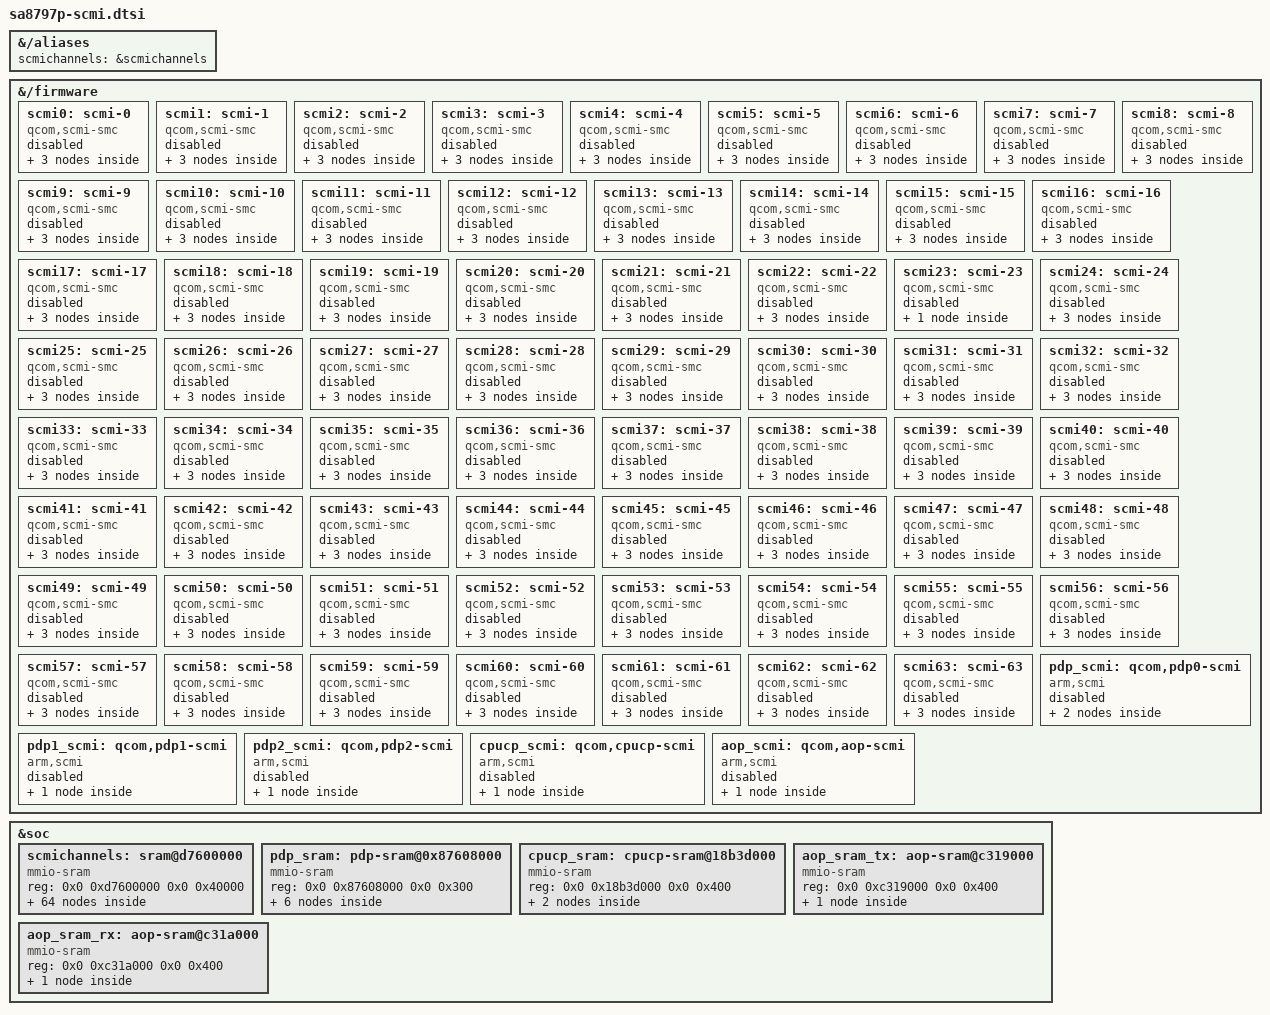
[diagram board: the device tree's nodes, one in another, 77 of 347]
/*
 * Copyright (c) Qualcomm Technologies, Inc. and/or its subsidiaries.
 * SPDX-License-Identifier: BSD-3-Clause
 */

#include <dt-bindings/interrupt-controller/arm-gic.h>
#include "oot-dt-bindings/qcom-ipcc-sa8797p.h"

&{/aliases} {
	scmichannels = &scmichannels;
};

&{/firmware} {
	scmi0: scmi-0 {
		compatible = "qcom,scmi-smc";
		arm,smc-id = <0xc6008012>;
		shmem = <&shmem0>;

		interrupts = <GIC_SPI 963 IRQ_TYPE_EDGE_RISING>;
		interrupt-names = "a2p";

		#address-cells = <1>;
		#size-cells = <0>;

		status = "disabled";

		scmi0_pd: protocol@11 {
			reg = <0x11>;
			#power-domain-cells = <1>;
		};

		scmi0_dvfs: protocol@13 {
			reg = <0x13>;
			#power-domain-cells = <1>;
		};

		scmi0_rst: protocol@16 {
			reg = <0x16>;
			#reset-cells = <1>;
		};
	};

	scmi1: scmi-1 {
		compatible = "qcom,scmi-smc";
		arm,smc-id = <0xc6008012>;
		shmem = <&shmem1>;

		interrupts = <GIC_SPI 964 IRQ_TYPE_EDGE_RISING>;
		interrupt-names = "a2p";

		#address-cells = <1>;
		#size-cells = <0>;

		status = "disabled";

		scmi1_pd: protocol@11 {
			reg = <0x11>;
			#power-domain-cells = <1>;
		};

		scmi1_dvfs: protocol@13 {
			reg = <0x13>;
			#power-domain-cells = <1>;
		};

		scmi1_rst: protocol@16 {
			reg = <0x16>;
			#reset-cells = <1>;
		};
	};

	scmi2: scmi-2 {
		compatible = "qcom,scmi-smc";
		arm,smc-id = <0xc6008012>;
		shmem = <&shmem2>;

		interrupts = <GIC_SPI 965 IRQ_TYPE_EDGE_RISING>;
		interrupt-names = "a2p";

		#address-cells = <1>;
		#size-cells = <0>;

		status = "disabled";

		scmi2_pd: protocol@11 {
			reg = <0x11>;
			#power-domain-cells = <1>;
		};

		scmi2_dvfs: protocol@13 {
			reg = <0x13>;
			#power-domain-cells = <1>;
		};

		scmi2_rst: protocol@16 {
			reg = <0x16>;
			#reset-cells = <1>;
		};
	};

	scmi3: scmi-3 {
		compatible = "qcom,scmi-smc";
		arm,smc-id = <0xc6008012>;
		shmem = <&shmem3>;

		interrupts = <GIC_SPI 966 IRQ_TYPE_EDGE_RISING>;
		interrupt-names = "a2p";

		#address-cells = <1>;
		#size-cells = <0>;

		status = "disabled";

		scmi3_pd: protocol@11 {
			reg = <0x11>;
			#power-domain-cells = <1>;
		};

		scmi3_dvfs: protocol@13 {
			reg = <0x13>;
			#power-domain-cells = <1>;
		};

		scmi3_rst: protocol@16 {
			reg = <0x16>;
			#reset-cells = <1>;
		};
	};

	scmi4: scmi-4 {
		compatible = "qcom,scmi-smc";
		arm,smc-id = <0xc6008012>;
		shmem = <&shmem4>;

		interrupts = <GIC_SPI 967 IRQ_TYPE_EDGE_RISING>;
		interrupt-names = "a2p";

		#address-cells = <1>;
		#size-cells = <0>;

		status = "disabled";

		scmi4_pd: protocol@11 {
			reg = <0x11>;
			#power-domain-cells = <1>;
		};

		scmi4_dvfs: protocol@13 {
			reg = <0x13>;
			#power-domain-cells = <1>;
		};

		scmi4_rst: protocol@16 {
			reg = <0x16>;
			#reset-cells = <1>;
		};
	};

	scmi5: scmi-5 {
		compatible = "qcom,scmi-smc";
		arm,smc-id = <0xc6008012>;
		shmem = <&shmem5>;

		interrupts = <GIC_SPI 968 IRQ_TYPE_EDGE_RISING>;
		interrupt-names = "a2p";

		#address-cells = <1>;
		#size-cells = <0>;

		status = "disabled";

		scmi5_pd: protocol@11 {
			reg = <0x11>;
			#power-domain-cells = <1>;
		};

		scmi5_dvfs: protocol@13 {
			reg = <0x13>;
			#power-domain-cells = <1>;
		};

		scmi5_rst: protocol@16 {
			reg = <0x16>;
			#reset-cells = <1>;
		};
	};

	scmi6: scmi-6 {
		compatible = "qcom,scmi-smc";
		arm,smc-id = <0xc6008012>;
		shmem = <&shmem6>;

		interrupts = <GIC_SPI 969 IRQ_TYPE_EDGE_RISING>;
		interrupt-names = "a2p";

		#address-cells = <1>;
		#size-cells = <0>;

		status = "disabled";

		scmi6_pd: protocol@11 {
			reg = <0x11>;
			#power-domain-cells = <1>;
		};

		scmi6_dvfs: protocol@13 {
			reg = <0x13>;
			#power-domain-cells = <1>;
		};

		scmi6_rst: protocol@16 {
			reg = <0x16>;
			#reset-cells = <1>;
		};
	};

	scmi7: scmi-7 {
		compatible = "qcom,scmi-smc";
		arm,smc-id = <0xc6008012>;
		shmem = <&shmem7>;

		interrupts = <GIC_SPI 970 IRQ_TYPE_EDGE_RISING>;
		interrupt-names = "a2p";

		#address-cells = <1>;
		#size-cells = <0>;

		status = "disabled";

		scmi7_pd: protocol@11 {
			reg = <0x11>;
			#power-domain-cells = <1>;
		};

		scmi7_dvfs: protocol@13 {
			reg = <0x13>;
			#power-domain-cells = <1>;
		};

		scmi7_rst: protocol@16 {
			reg = <0x16>;
			#reset-cells = <1>;
		};
	};

	scmi8: scmi-8 {
		compatible = "qcom,scmi-smc";
		arm,smc-id = <0xc6008012>;
		shmem = <&shmem8>;

		interrupts = <GIC_SPI 971 IRQ_TYPE_EDGE_RISING>;
		interrupt-names = "a2p";

		#address-cells = <1>;
		#size-cells = <0>;

		status = "disabled";

		scmi8_pd: protocol@11 {
			reg = <0x11>;
			#power-domain-cells = <1>;
		};

		scmi8_dvfs: protocol@13 {
			reg = <0x13>;
			#power-domain-cells = <1>;
		};

		scmi8_rst: protocol@16 {
			reg = <0x16>;
			#reset-cells = <1>;
		};
	};

	scmi9: scmi-9 {
		compatible = "qcom,scmi-smc";
		arm,smc-id = <0xc6008012>;
		shmem = <&shmem9>;

		interrupts = <GIC_SPI 972 IRQ_TYPE_EDGE_RISING>;
		interrupt-names = "a2p";

		#address-cells = <1>;
		#size-cells = <0>;

		status = "disabled";

		scmi9_pd: protocol@11 {
			reg = <0x11>;
			#power-domain-cells = <1>;
		};

		scmi9_dvfs: protocol@13 {
			reg = <0x13>;
			#power-domain-cells = <1>;
		};

		scmi9_rst: protocol@16 {
			reg = <0x16>;
			#reset-cells = <1>;
		};
	};

	scmi10: scmi-10 {
		compatible = "qcom,scmi-smc";
		arm,smc-id = <0xc6008012>;
		shmem = <&shmem10>;

		interrupts = <GIC_SPI 973 IRQ_TYPE_EDGE_RISING>;
		interrupt-names = "a2p";

		#address-cells = <1>;
		#size-cells = <0>;

		status = "disabled";

		scmi10_pd: protocol@11 {
			reg = <0x11>;
			#power-domain-cells = <1>;
		};

		scmi10_dvfs: protocol@13 {
			reg = <0x13>;
			#power-domain-cells = <1>;
		};

		scmi10_rst: protocol@16 {
			reg = <0x16>;
			#reset-cells = <1>;
		};
	};

	scmi11: scmi-11 {
		compatible = "qcom,scmi-smc";
		arm,smc-id = <0xc6008012>;
		shmem = <&shmem11>;

		interrupts = <GIC_SPI 974 IRQ_TYPE_EDGE_RISING>;
		interrupt-names = "a2p";

		#address-cells = <1>;
		#size-cells = <0>;

		status = "disabled";

		scmi11_pd: protocol@11 {
			reg = <0x11>;
			#power-domain-cells = <1>;
		};

		scmi11_dvfs: protocol@13 {
			reg = <0x13>;
			#power-domain-cells = <1>;
		};

		scmi11_rst: protocol@16 {
			reg = <0x16>;
			#reset-cells = <1>;
		};
	};

	scmi12: scmi-12 {
		compatible = "qcom,scmi-smc";
		arm,smc-id = <0xc6008012>;
		shmem = <&shmem12>;

		interrupts = <GIC_SPI 975 IRQ_TYPE_EDGE_RISING>;
		interrupt-names = "a2p";

		#address-cells = <1>;
		#size-cells = <0>;

		status = "disabled";

		scmi12_pd: protocol@11 {
			reg = <0x11>;
			#power-domain-cells = <1>;
		};

		scmi12_dvfs: protocol@13 {
			reg = <0x13>;
			#power-domain-cells = <1>;
		};

		scmi12_rst: protocol@16 {
			reg = <0x16>;
			#reset-cells = <1>;
		};
	};

	scmi13: scmi-13 {
		compatible = "qcom,scmi-smc";
		arm,smc-id = <0xc6008012>;
		shmem = <&shmem13>;

		interrupts = <GIC_SPI 976 IRQ_TYPE_EDGE_RISING>;
		interrupt-names = "a2p";

		#address-cells = <1>;
		#size-cells = <0>;

		status = "disabled";

		scmi13_pd: protocol@11 {
			reg = <0x11>;
			#power-domain-cells = <1>;
		};

		scmi13_dvfs: protocol@13 {
			reg = <0x13>;
			#power-domain-cells = <1>;
		};

		scmi13_rst: protocol@16 {
			reg = <0x16>;
			#reset-cells = <1>;
		};
	};

	scmi14: scmi-14 {
		compatible = "qcom,scmi-smc";
		arm,smc-id = <0xc6008012>;
		shmem = <&shmem14>;

		interrupts = <GIC_SPI 977 IRQ_TYPE_EDGE_RISING>;
		interrupt-names = "a2p";

		#address-cells = <1>;
		#size-cells = <0>;

		status = "disabled";

		scmi14_pd: protocol@11 {
			reg = <0x11>;
			#power-domain-cells = <1>;
		};

		scmi14_dvfs: protocol@13 {
			reg = <0x13>;
			#power-domain-cells = <1>;
		};

		scmi14_rst: protocol@16 {
			reg = <0x16>;
			#reset-cells = <1>;
		};
	};

	scmi15: scmi-15 {
		compatible = "qcom,scmi-smc";
		arm,smc-id = <0xc6008012>;
		shmem = <&shmem15>;

		interrupts = <GIC_SPI 978 IRQ_TYPE_EDGE_RISING>;
		interrupt-names = "a2p";

		#address-cells = <1>;
		#size-cells = <0>;

		status = "disabled";

		scmi15_pd: protocol@11 {
			reg = <0x11>;
			#power-domain-cells = <1>;
		};

		scmi15_dvfs: protocol@13 {
			reg = <0x13>;
			#power-domain-cells = <1>;
		};

		scmi15_rst: protocol@16 {
			reg = <0x16>;
			#reset-cells = <1>;
		};
	};

	scmi16: scmi-16 {
		compatible = "qcom,scmi-smc";
		arm,smc-id = <0xc6008012>;
		shmem = <&shmem16>;

		interrupts = <GIC_SPI 979 IRQ_TYPE_EDGE_RISING>;
		interrupt-names = "a2p";

		#address-cells = <1>;
		#size-cells = <0>;

		status = "disabled";

		scmi16_pd: protocol@11 {
			reg = <0x11>;
			#power-domain-cells = <1>;
		};

		scmi16_dvfs: protocol@13 {
			reg = <0x13>;
			#power-domain-cells = <1>;
		};

		scmi16_rst: protocol@16 {
			reg = <0x16>;
			#reset-cells = <1>;
		};
	};

	scmi17: scmi-17 {
		compatible = "qcom,scmi-smc";
		arm,smc-id = <0xc6008012>;
		shmem = <&shmem17>;

		interrupts = <GIC_SPI 980 IRQ_TYPE_EDGE_RISING>;
		interrupt-names = "a2p";

		#address-cells = <1>;
		#size-cells = <0>;

		status = "disabled";

		scmi17_pd: protocol@11 {
			reg = <0x11>;
			#power-domain-cells = <1>;
		};

		scmi17_dvfs: protocol@13 {
			reg = <0x13>;
			#power-domain-cells = <1>;
		};

		scmi17_rst: protocol@16 {
			reg = <0x16>;
			#reset-cells = <1>;
		};
	};

	scmi18: scmi-18 {
		compatible = "qcom,scmi-smc";
		arm,smc-id = <0xc6008012>;
		shmem = <&shmem18>;

		interrupts = <GIC_SPI 981 IRQ_TYPE_EDGE_RISING>;
		interrupt-names = "a2p";

		#address-cells = <1>;
		#size-cells = <0>;

		status = "disabled";

		scmi18_pd: protocol@11 {
			reg = <0x11>;
			#power-domain-cells = <1>;
		};

		scmi18_dvfs: protocol@13 {
			reg = <0x13>;
			#power-domain-cells = <1>;
		};

		scmi18_rst: protocol@16 {
			reg = <0x16>;
			#reset-cells = <1>;
		};
	};

	scmi19: scmi-19 {
		compatible = "qcom,scmi-smc";
		arm,smc-id = <0xc6008012>;
		shmem = <&shmem19>;

		interrupts = <GIC_SPI 982 IRQ_TYPE_EDGE_RISING>;
		interrupt-names = "a2p";

		#address-cells = <1>;
		#size-cells = <0>;

		status = "disabled";

		scmi19_pd: protocol@11 {
			reg = <0x11>;
			#power-domain-cells = <1>;
		};

		scmi19_dvfs: protocol@13 {
			reg = <0x13>;
			#power-domain-cells = <1>;
		};

		scmi19_rst: protocol@16 {
			reg = <0x16>;
			#reset-cells = <1>;
		};
	};

	scmi20: scmi-20 {
		compatible = "qcom,scmi-smc";
		arm,smc-id = <0xc6008012>;
		shmem = <&shmem20>;

		interrupts = <GIC_SPI 983 IRQ_TYPE_EDGE_RISING>;
		interrupt-names = "a2p";

		#address-cells = <1>;
		#size-cells = <0>;

		status = "disabled";

		scmi20_pd: protocol@11 {
			reg = <0x11>;
			#power-domain-cells = <1>;
		};

		scmi20_dvfs: protocol@13 {
			reg = <0x13>;
			#power-domain-cells = <1>;
		};

		scmi20_rst: protocol@16 {
			reg = <0x16>;
			#reset-cells = <1>;
		};
	};

	scmi21: scmi-21 {
		compatible = "qcom,scmi-smc";
		arm,smc-id = <0xc6008012>;
		shmem = <&shmem21>;

		interrupts = <GIC_SPI 984 IRQ_TYPE_EDGE_RISING>;
		interrupt-names = "a2p";

		#address-cells = <1>;
		#size-cells = <0>;

		status = "disabled";

		scmi21_pd: protocol@11 {
			reg = <0x11>;
			#power-domain-cells = <1>;
		};

		scmi21_dvfs: protocol@13 {
			reg = <0x13>;
			#power-domain-cells = <1>;
		};

		scmi21_rst: protocol@16 {
			reg = <0x16>;
			#reset-cells = <1>;
		};
	};

	scmi22: scmi-22 {
		compatible = "qcom,scmi-smc";
		arm,smc-id = <0xc6008012>;
		shmem = <&shmem22>;

		interrupts = <GIC_SPI 985 IRQ_TYPE_EDGE_RISING>;
		interrupt-names = "a2p";

		#address-cells = <1>;
		#size-cells = <0>;

		status = "disabled";

		scmi22_pd: protocol@11 {
			reg = <0x11>;
			#power-domain-cells = <1>;
		};

		scmi22_dvfs: protocol@13 {
			reg = <0x13>;
			#power-domain-cells = <1>;
		};

		scmi22_rst: protocol@16 {
			reg = <0x16>;
			#reset-cells = <1>;
		};
	};

	scmi23: scmi-23 {
		compatible = "qcom,scmi-smc";
		arm,smc-id = <0xc6008012>;
		shmem = <&shmem23>;

		interrupts = <GIC_SPI 986 IRQ_TYPE_EDGE_RISING>;
		interrupt-names = "a2p";

		#address-cells = <1>;
		#size-cells = <0>;

		status = "disabled";

		scmi23_sensor: protocol@15 {
			reg = <0x15>;
			#thermal-sensor-cells = <1>;
		};
	};

	scmi24: scmi-24 {
		compatible = "qcom,scmi-smc";
		arm,smc-id = <0xc6008012>;
		shmem = <&shmem24>;

		interrupts = <GIC_SPI 987 IRQ_TYPE_EDGE_RISING>;
		interrupt-names = "a2p";

		#address-cells = <1>;
		#size-cells = <0>;

		status = "disabled";

		scmi24_pd: protocol@11 {
			reg = <0x11>;
			#power-domain-cells = <1>;
		};

		scmi24_dvfs: protocol@13 {
			reg = <0x13>;
			#power-domain-cells = <1>;
		};

		scmi24_rst: protocol@16 {
			reg = <0x16>;
			#reset-cells = <1>;
		};
	};

	scmi25: scmi-25 {
		compatible = "qcom,scmi-smc";
		arm,smc-id = <0xc6008012>;
		shmem = <&shmem25>;

		interrupts = <GIC_ESPI 0 IRQ_TYPE_EDGE_RISING>;
		interrupt-names = "a2p";

		#address-cells = <1>;
		#size-cells = <0>;

		status = "disabled";

		scmi25_pd: protocol@11 {
			reg = <0x11>;
			#power-domain-cells = <1>;
		};

		scmi25_dvfs: protocol@13 {
			reg = <0x13>;
			#power-domain-cells = <1>;
		};

		scmi25_rst: protocol@16 {
			reg = <0x16>;
			#reset-cells = <1>;
		};
	};

	scmi26: scmi-26 {
		compatible = "qcom,scmi-smc";
		arm,smc-id = <0xc6008012>;
		shmem = <&shmem26>;

		interrupts = <GIC_ESPI 1 IRQ_TYPE_EDGE_RISING>;
		interrupt-names = "a2p";

		#address-cells = <1>;
		#size-cells = <0>;

		status = "disabled";

		scmi26_pd: protocol@11 {
			reg = <0x11>;
			#power-domain-cells = <1>;
		};

		scmi26_dvfs: protocol@13 {
			reg = <0x13>;
			#power-domain-cells = <1>;
		};

		scmi26_rst: protocol@16 {
			reg = <0x16>;
			#reset-cells = <1>;
		};
	};

	scmi27: scmi-27 {
		compatible = "qcom,scmi-smc";
		arm,smc-id = <0xc6008012>;
		shmem = <&shmem27>;

		interrupts = <GIC_ESPI 2 IRQ_TYPE_EDGE_RISING>;
		interrupt-names = "a2p";

		#address-cells = <1>;
		#size-cells = <0>;

		status = "disabled";

		scmi27_pd: protocol@11 {
			reg = <0x11>;
			#power-domain-cells = <1>;
		};

		scmi27_dvfs: protocol@13 {
			reg = <0x13>;
			#power-domain-cells = <1>;
		};

		scmi27_rst: protocol@16 {
			reg = <0x16>;
			#reset-cells = <1>;
		};
	};

	scmi28: scmi-28 {
		compatible = "qcom,scmi-smc";
		arm,smc-id = <0xc6008012>;
		shmem = <&shmem28>;

		interrupts = <GIC_ESPI 3 IRQ_TYPE_EDGE_RISING>;
		interrupt-names = "a2p";

		#address-cells = <1>;
		#size-cells = <0>;

		status = "disabled";

		scmi28_pd: protocol@11 {
			reg = <0x11>;
			#power-domain-cells = <1>;
		};

		scmi28_dvfs: protocol@13 {
			reg = <0x13>;
			#power-domain-cells = <1>;
		};

		scmi28_rst: protocol@16 {
			reg = <0x16>;
			#reset-cells = <1>;
		};
	};

	scmi29: scmi-29 {
		compatible = "qcom,scmi-smc";
		arm,smc-id = <0xc6008012>;
		shmem = <&shmem29>;

		interrupts = <GIC_ESPI 4 IRQ_TYPE_EDGE_RISING>;
		interrupt-names = "a2p";

		#address-cells = <1>;
		#size-cells = <0>;

		status = "disabled";

		scmi29_pd: protocol@11 {
			reg = <0x11>;
			#power-domain-cells = <1>;
		};

		scmi29_dvfs: protocol@13 {
			reg = <0x13>;
			#power-domain-cells = <1>;
		};

		scmi29_rst: protocol@16 {
			reg = <0x16>;
			#reset-cells = <1>;
		};
	};

	scmi30: scmi-30 {
		compatible = "qcom,scmi-smc";
		arm,smc-id = <0xc6008012>;
		shmem = <&shmem30>;

		interrupts = <GIC_ESPI 5 IRQ_TYPE_EDGE_RISING>;
		interrupt-names = "a2p";

		#address-cells = <1>;
		#size-cells = <0>;

		status = "disabled";

		scmi30_pd: protocol@11 {
			reg = <0x11>;
			#power-domain-cells = <1>;
		};

		scmi30_dvfs: protocol@13 {
			reg = <0x13>;
			#power-domain-cells = <1>;
		};

		scmi30_rst: protocol@16 {
			reg = <0x16>;
			#reset-cells = <1>;
		};
	};

	scmi31: scmi-31 {
		compatible = "qcom,scmi-smc";
		arm,smc-id = <0xc6008012>;
		shmem = <&shmem31>;

		interrupts = <GIC_ESPI 6 IRQ_TYPE_EDGE_RISING>;
		interrupt-names = "a2p";

		#address-cells = <1>;
		#size-cells = <0>;

		status = "disabled";

		scmi31_pd: protocol@11 {
			reg = <0x11>;
			#power-domain-cells = <1>;
		};

		scmi31_dvfs: protocol@13 {
			reg = <0x13>;
			#power-domain-cells = <1>;
		};

		scmi31_rst: protocol@16 {
			reg = <0x16>;
			#reset-cells = <1>;
		};
	};

	scmi32: scmi-32 {
		compatible = "qcom,scmi-smc";
		arm,smc-id = <0xc6008012>;
		shmem = <&shmem32>;

		interrupts = <GIC_ESPI 7 IRQ_TYPE_EDGE_RISING>;
		interrupt-names = "a2p";

		#address-cells = <1>;
		#size-cells = <0>;

		status = "disabled";

		scmi32_pd: protocol@11 {
			reg = <0x11>;
			#power-domain-cells = <1>;
		};

		scmi32_dvfs: protocol@13 {
			reg = <0x13>;
			#power-domain-cells = <1>;
		};

		scmi32_rst: protocol@16 {
			reg = <0x16>;
			#reset-cells = <1>;
		};
	};

	scmi33: scmi-33 {
		compatible = "qcom,scmi-smc";
		arm,smc-id = <0xc6008012>;
		shmem = <&shmem33>;

		interrupts = <GIC_ESPI 8 IRQ_TYPE_EDGE_RISING>;
		interrupt-names = "a2p";

		#address-cells = <1>;
		#size-cells = <0>;

		status = "disabled";

		scmi33_pd: protocol@11 {
			reg = <0x11>;
			#power-domain-cells = <1>;
		};

		scmi33_dvfs: protocol@13 {
			reg = <0x13>;
			#power-domain-cells = <1>;
		};

		scmi33_rst: protocol@16 {
			reg = <0x16>;
			#reset-cells = <1>;
		};
	};

	scmi34: scmi-34 {
		compatible = "qcom,scmi-smc";
		arm,smc-id = <0xc6008012>;
		shmem = <&shmem34>;

		interrupts = <GIC_ESPI 9 IRQ_TYPE_EDGE_RISING>;
		interrupt-names = "a2p";

		#address-cells = <1>;
		#size-cells = <0>;

		status = "disabled";

		scmi34_pd: protocol@11 {
			reg = <0x11>;
			#power-domain-cells = <1>;
		};

		scmi34_dvfs: protocol@13 {
			reg = <0x13>;
			#power-domain-cells = <1>;
		};

		scmi34_rst: protocol@16 {
			reg = <0x16>;
			#reset-cells = <1>;
		};
	};

	scmi35: scmi-35 {
		compatible = "qcom,scmi-smc";
		arm,smc-id = <0xc6008012>;
		shmem = <&shmem35>;

		interrupts = <GIC_ESPI 10 IRQ_TYPE_EDGE_RISING>;
		interrupt-names = "a2p";

		#address-cells = <1>;
		#size-cells = <0>;

		status = "disabled";

		scmi35_pd: protocol@11 {
			reg = <0x11>;
			#power-domain-cells = <1>;
		};

		scmi35_dvfs: protocol@13 {
			reg = <0x13>;
			#power-domain-cells = <1>;
		};

		scmi35_rst: protocol@16 {
			reg = <0x16>;
			#reset-cells = <1>;
		};
	};

	scmi36: scmi-36 {
		compatible = "qcom,scmi-smc";
		arm,smc-id = <0xc6008012>;
		shmem = <&shmem36>;

		interrupts = <GIC_ESPI 11 IRQ_TYPE_EDGE_RISING>;
		interrupt-names = "a2p";

		#address-cells = <1>;
		#size-cells = <0>;

		status = "disabled";

		scmi36_pd: protocol@11 {
			reg = <0x11>;
			#power-domain-cells = <1>;
		};

		scmi36_dvfs: protocol@13 {
			reg = <0x13>;
			#power-domain-cells = <1>;
		};

		scmi36_rst: protocol@16 {
			reg = <0x16>;
			#reset-cells = <1>;
		};
	};

	scmi37: scmi-37 {
		compatible = "qcom,scmi-smc";
		arm,smc-id = <0xc6008012>;
		shmem = <&shmem37>;

		interrupts = <GIC_ESPI 12 IRQ_TYPE_EDGE_RISING>;
		interrupt-names = "a2p";

		#address-cells = <1>;
		#size-cells = <0>;

		status = "disabled";

		scmi37_pd: protocol@11 {
			reg = <0x11>;
			#power-domain-cells = <1>;
		};

		scmi37_dvfs: protocol@13 {
			reg = <0x13>;
			#power-domain-cells = <1>;
		};

		scmi37_rst: protocol@16 {
			reg = <0x16>;
			#reset-cells = <1>;
		};
	};

	scmi38: scmi-38 {
		compatible = "qcom,scmi-smc";
		arm,smc-id = <0xc6008012>;
		shmem = <&shmem38>;

		interrupts = <GIC_ESPI 13 IRQ_TYPE_EDGE_RISING>;
		interrupt-names = "a2p";

		#address-cells = <1>;
		#size-cells = <0>;

		status = "disabled";

		scmi38_pd: protocol@11 {
			reg = <0x11>;
			#power-domain-cells = <1>;
		};

		scmi38_dvfs: protocol@13 {
			reg = <0x13>;
			#power-domain-cells = <1>;
		};

		scmi38_rst: protocol@16 {
			reg = <0x16>;
			#reset-cells = <1>;
		};
	};

	scmi39: scmi-39 {
		compatible = "qcom,scmi-smc";
		arm,smc-id = <0xc6008012>;
		shmem = <&shmem39>;

		interrupts = <GIC_ESPI 14 IRQ_TYPE_EDGE_RISING>;
		interrupt-names = "a2p";

		#address-cells = <1>;
		#size-cells = <0>;

		status = "disabled";

		scmi39_pd: protocol@11 {
			reg = <0x11>;
			#power-domain-cells = <1>;
		};

		scmi39_dvfs: protocol@13 {
			reg = <0x13>;
			#power-domain-cells = <1>;
		};

		scmi39_rst: protocol@16 {
			reg = <0x16>;
			#reset-cells = <1>;
		};
	};

	scmi40: scmi-40 {
		compatible = "qcom,scmi-smc";
		arm,smc-id = <0xc6008012>;
		shmem = <&shmem40>;

		interrupts = <GIC_ESPI 15 IRQ_TYPE_EDGE_RISING>;
		interrupt-names = "a2p";

		#address-cells = <1>;
		#size-cells = <0>;

		status = "disabled";

		scmi40_pd: protocol@11 {
			reg = <0x11>;
			#power-domain-cells = <1>;
		};

		scmi40_dvfs: protocol@13 {
			reg = <0x13>;
			#power-domain-cells = <1>;
		};

		scmi40_rst: protocol@16 {
			reg = <0x16>;
			#reset-cells = <1>;
		};
	};

	scmi41: scmi-41 {
		compatible = "qcom,scmi-smc";
		arm,smc-id = <0xc6008012>;
		shmem = <&shmem41>;

		interrupts = <GIC_ESPI 16 IRQ_TYPE_EDGE_RISING>;
		interrupt-names = "a2p";

		#address-cells = <1>;
		#size-cells = <0>;

		status = "disabled";

		scmi41_pd: protocol@11 {
			reg = <0x11>;
			#power-domain-cells = <1>;
		};

		scmi41_dvfs: protocol@13 {
			reg = <0x13>;
			#power-domain-cells = <1>;
		};

		scmi41_rst: protocol@16 {
			reg = <0x16>;
			#reset-cells = <1>;
		};
	};

	scmi42: scmi-42 {
		compatible = "qcom,scmi-smc";
		arm,smc-id = <0xc6008012>;
		shmem = <&shmem42>;

		interrupts = <GIC_ESPI 17 IRQ_TYPE_EDGE_RISING>;
		interrupt-names = "a2p";

		#address-cells = <1>;
		#size-cells = <0>;

		status = "disabled";

		scmi42_pd: protocol@11 {
			reg = <0x11>;
			#power-domain-cells = <1>;
		};

		scmi42_dvfs: protocol@13 {
			reg = <0x13>;
			#power-domain-cells = <1>;
		};

		scmi42_rst: protocol@16 {
			reg = <0x16>;
			#reset-cells = <1>;
		};
	};

	scmi43: scmi-43 {
		compatible = "qcom,scmi-smc";
		arm,smc-id = <0xc6008012>;
		shmem = <&shmem43>;

		interrupts = <GIC_ESPI 18 IRQ_TYPE_EDGE_RISING>;
		interrupt-names = "a2p";

		#address-cells = <1>;
		#size-cells = <0>;

		status = "disabled";

		scmi43_pd: protocol@11 {
			reg = <0x11>;
			#power-domain-cells = <1>;
		};

		scmi43_dvfs: protocol@13 {
			reg = <0x13>;
			#power-domain-cells = <1>;
		};

		scmi43_rst: protocol@16 {
			reg = <0x16>;
			#reset-cells = <1>;
		};
	};

	scmi44: scmi-44 {
		compatible = "qcom,scmi-smc";
		arm,smc-id = <0xc6008012>;
		shmem = <&shmem44>;

		interrupts = <GIC_ESPI 19 IRQ_TYPE_EDGE_RISING>;
		interrupt-names = "a2p";

		#address-cells = <1>;
		#size-cells = <0>;

		status = "disabled";

		scmi44_pd: protocol@11 {
			reg = <0x11>;
			#power-domain-cells = <1>;
		};

		scmi44_dvfs: protocol@13 {
			reg = <0x13>;
			#power-domain-cells = <1>;
		};

		scmi44_rst: protocol@16 {
			reg = <0x16>;
			#reset-cells = <1>;
		};
	};

	scmi45: scmi-45 {
		compatible = "qcom,scmi-smc";
		arm,smc-id = <0xc6008012>;
		shmem = <&shmem45>;

		interrupts = <GIC_ESPI 20 IRQ_TYPE_EDGE_RISING>;
		interrupt-names = "a2p";

		#address-cells = <1>;
		#size-cells = <0>;

		status = "disabled";

		scmi45_pd: protocol@11 {
			reg = <0x11>;
			#power-domain-cells = <1>;
		};

		scmi45_dvfs: protocol@13 {
			reg = <0x13>;
			#power-domain-cells = <1>;
		};

		scmi45_rst: protocol@16 {
			reg = <0x16>;
			#reset-cells = <1>;
		};
	};

	scmi46: scmi-46 {
		compatible = "qcom,scmi-smc";
		arm,smc-id = <0xc6008012>;
		shmem = <&shmem46>;

		interrupts = <GIC_ESPI 21 IRQ_TYPE_EDGE_RISING>;
		interrupt-names = "a2p";

		#address-cells = <1>;
		#size-cells = <0>;

		status = "disabled";

		scmi46_pd: protocol@11 {
			reg = <0x11>;
			#power-domain-cells = <1>;
		};

		scmi46_dvfs: protocol@13 {
			reg = <0x13>;
			#power-domain-cells = <1>;
		};

		scmi46_rst: protocol@16 {
			reg = <0x16>;
			#reset-cells = <1>;
		};
	};

	scmi47: scmi-47 {
		compatible = "qcom,scmi-smc";
		arm,smc-id = <0xc6008012>;
		shmem = <&shmem47>;

		interrupts = <GIC_ESPI 22 IRQ_TYPE_EDGE_RISING>;
		interrupt-names = "a2p";

		#address-cells = <1>;
		#size-cells = <0>;

		status = "disabled";

		scmi47_pd: protocol@11 {
			reg = <0x11>;
			#power-domain-cells = <1>;
		};

		scmi47_dvfs: protocol@13 {
			reg = <0x13>;
			#power-domain-cells = <1>;
		};

		scmi47_rst: protocol@16 {
			reg = <0x16>;
			#reset-cells = <1>;
		};
	};

	scmi48: scmi-48 {
		compatible = "qcom,scmi-smc";
		arm,smc-id = <0xc6008012>;
		shmem = <&shmem48>;

		interrupts = <GIC_ESPI 23 IRQ_TYPE_EDGE_RISING>;
		interrupt-names = "a2p";

		#address-cells = <1>;
		#size-cells = <0>;

		status = "disabled";

		scmi48_pd: protocol@11 {
			reg = <0x11>;
			#power-domain-cells = <1>;
		};

		scmi48_dvfs: protocol@13 {
			reg = <0x13>;
			#power-domain-cells = <1>;
		};

		scmi48_rst: protocol@16 {
			reg = <0x16>;
			#reset-cells = <1>;
		};
	};

	scmi49: scmi-49 {
		compatible = "qcom,scmi-smc";
		arm,smc-id = <0xc6008012>;
		shmem = <&shmem49>;

		interrupts = <GIC_ESPI 24 IRQ_TYPE_EDGE_RISING>;
		interrupt-names = "a2p";

		#address-cells = <1>;
		#size-cells = <0>;

		status = "disabled";

		scmi49_pd: protocol@11 {
			reg = <0x11>;
			#power-domain-cells = <1>;
		};

		scmi49_dvfs: protocol@13 {
			reg = <0x13>;
			#power-domain-cells = <1>;
		};

		scmi49_rst: protocol@16 {
			reg = <0x16>;
			#reset-cells = <1>;
		};
	};

	scmi50: scmi-50 {
		compatible = "qcom,scmi-smc";
		arm,smc-id = <0xc6008012>;
		shmem = <&shmem50>;

		interrupts = <GIC_ESPI 25 IRQ_TYPE_EDGE_RISING>;
		interrupt-names = "a2p";

		#address-cells = <1>;
		#size-cells = <0>;

		status = "disabled";

		scmi50_pd: protocol@11 {
			reg = <0x11>;
			#power-domain-cells = <1>;
		};

		scmi50_dvfs: protocol@13 {
			reg = <0x13>;
			#power-domain-cells = <1>;
		};

		scmi50_rst: protocol@16 {
			reg = <0x16>;
			#reset-cells = <1>;
		};
	};

	scmi51: scmi-51 {
		compatible = "qcom,scmi-smc";
		arm,smc-id = <0xc6008012>;
		shmem = <&shmem51>;

		interrupts = <GIC_ESPI 26 IRQ_TYPE_EDGE_RISING>;
		interrupt-names = "a2p";

		#address-cells = <1>;
		#size-cells = <0>;

		status = "disabled";

		scmi51_pd: protocol@11 {
			reg = <0x11>;
			#power-domain-cells = <1>;
		};

		scmi51_dvfs: protocol@13 {
			reg = <0x13>;
			#power-domain-cells = <1>;
		};

		scmi51_rst: protocol@16 {
			reg = <0x16>;
			#reset-cells = <1>;
		};
	};

	scmi52: scmi-52 {
		compatible = "qcom,scmi-smc";
		arm,smc-id = <0xc6008012>;
		shmem = <&shmem52>;

		interrupts = <GIC_ESPI 27 IRQ_TYPE_EDGE_RISING>;
		interrupt-names = "a2p";

		#address-cells = <1>;
		#size-cells = <0>;

		status = "disabled";

		scmi52_pd: protocol@11 {
			reg = <0x11>;
			#power-domain-cells = <1>;
		};

		scmi52_dvfs: protocol@13 {
			reg = <0x13>;
			#power-domain-cells = <1>;
		};

		scmi52_rst: protocol@16 {
			reg = <0x16>;
			#reset-cells = <1>;
		};
	};

	scmi53: scmi-53 {
		compatible = "qcom,scmi-smc";
		arm,smc-id = <0xc6008012>;
		shmem = <&shmem53>;

		interrupts = <GIC_ESPI 28 IRQ_TYPE_EDGE_RISING>;
		interrupt-names = "a2p";

		#address-cells = <1>;
		#size-cells = <0>;

		status = "disabled";

		scmi53_pd: protocol@11 {
			reg = <0x11>;
			#power-domain-cells = <1>;
		};

		scmi53_dvfs: protocol@13 {
			reg = <0x13>;
			#power-domain-cells = <1>;
		};

		scmi53_rst: protocol@16 {
			reg = <0x16>;
			#reset-cells = <1>;
		};
	};

	scmi54: scmi-54 {
		compatible = "qcom,scmi-smc";
		arm,smc-id = <0xc6008012>;
		shmem = <&shmem54>;

		interrupts = <GIC_ESPI 29 IRQ_TYPE_EDGE_RISING>;
		interrupt-names = "a2p";

		#address-cells = <1>;
		#size-cells = <0>;

		status = "disabled";

		scmi54_pd: protocol@11 {
			reg = <0x11>;
			#power-domain-cells = <1>;
		};

		scmi54_dvfs: protocol@13 {
			reg = <0x13>;
			#power-domain-cells = <1>;
		};

		scmi54_rst: protocol@16 {
			reg = <0x16>;
			#reset-cells = <1>;
		};
	};

	scmi55: scmi-55 {
		compatible = "qcom,scmi-smc";
		arm,smc-id = <0xc6008012>;
		shmem = <&shmem55>;

		interrupts = <GIC_ESPI 30 IRQ_TYPE_EDGE_RISING>;
		interrupt-names = "a2p";

		#address-cells = <1>;
		#size-cells = <0>;

		status = "disabled";

		scmi55_pd: protocol@11 {
			reg = <0x11>;
			#power-domain-cells = <1>;
		};

		scmi55_dvfs: protocol@13 {
			reg = <0x13>;
			#power-domain-cells = <1>;
		};

		scmi55_rst: protocol@16 {
			reg = <0x16>;
			#reset-cells = <1>;
		};
	};

	scmi56: scmi-56 {
		compatible = "qcom,scmi-smc";
		arm,smc-id = <0xc6008012>;
		shmem = <&shmem56>;

		interrupts = <GIC_ESPI 31 IRQ_TYPE_EDGE_RISING>;
		interrupt-names = "a2p";

		#address-cells = <1>;
		#size-cells = <0>;

		status = "disabled";

		scmi56_pd: protocol@11 {
			reg = <0x11>;
			#power-domain-cells = <1>;
		};

		scmi56_dvfs: protocol@13 {
			reg = <0x13>;
			#power-domain-cells = <1>;
		};

		scmi56_rst: protocol@16 {
			reg = <0x16>;
			#reset-cells = <1>;
		};
	};

	scmi57: scmi-57 {
		compatible = "qcom,scmi-smc";
		arm,smc-id = <0xc6008012>;
		shmem = <&shmem57>;

		interrupts = <GIC_ESPI 32 IRQ_TYPE_EDGE_RISING>;
		interrupt-names = "a2p";

		#address-cells = <1>;
		#size-cells = <0>;

		status = "disabled";

		scmi57_pd: protocol@11 {
			reg = <0x11>;
			#power-domain-cells = <1>;
		};

		scmi57_dvfs: protocol@13 {
			reg = <0x13>;
			#power-domain-cells = <1>;
		};

		scmi57_rst: protocol@16 {
			reg = <0x16>;
			#reset-cells = <1>;
		};
	};

	scmi58: scmi-58 {
		compatible = "qcom,scmi-smc";
		arm,smc-id = <0xc6008012>;
		shmem = <&shmem58>;

		interrupts = <GIC_ESPI 33 IRQ_TYPE_EDGE_RISING>;
		interrupt-names = "a2p";

		#address-cells = <1>;
		#size-cells = <0>;

		status = "disabled";

		scmi58_pd: protocol@11 {
			reg = <0x11>;
			#power-domain-cells = <1>;
		};

		scmi58_dvfs: protocol@13 {
			reg = <0x13>;
			#power-domain-cells = <1>;
		};

		scmi58_rst: protocol@16 {
			reg = <0x16>;
			#reset-cells = <1>;
		};
	};

	scmi59: scmi-59 {
		compatible = "qcom,scmi-smc";
		arm,smc-id = <0xc6008012>;
		shmem = <&shmem59>;

		interrupts = <GIC_ESPI 34 IRQ_TYPE_EDGE_RISING>;
		interrupt-names = "a2p";

		#address-cells = <1>;
		#size-cells = <0>;

		status = "disabled";

		scmi59_pd: protocol@11 {
			reg = <0x11>;
			#power-domain-cells = <1>;
		};

		scmi59_dvfs: protocol@13 {
			reg = <0x13>;
			#power-domain-cells = <1>;
		};

		scmi59_rst: protocol@16 {
			reg = <0x16>;
			#reset-cells = <1>;
		};
	};

	scmi60: scmi-60 {
		compatible = "qcom,scmi-smc";
		arm,smc-id = <0xc6008012>;
		shmem = <&shmem60>;

		interrupts = <GIC_ESPI 35 IRQ_TYPE_EDGE_RISING>;
		interrupt-names = "a2p";

		#address-cells = <1>;
		#size-cells = <0>;

		status = "disabled";

		scmi60_pd: protocol@11 {
			reg = <0x11>;
			#power-domain-cells = <1>;
		};

		scmi60_dvfs: protocol@13 {
			reg = <0x13>;
			#power-domain-cells = <1>;
		};

		scmi60_rst: protocol@16 {
			reg = <0x16>;
			#reset-cells = <1>;
		};
	};

	scmi61: scmi-61 {
		compatible = "qcom,scmi-smc";
		arm,smc-id = <0xc6008012>;
		shmem = <&shmem61>;

		interrupts = <GIC_ESPI 36 IRQ_TYPE_EDGE_RISING>;
		interrupt-names = "a2p";

		#address-cells = <1>;
		#size-cells = <0>;

		status = "disabled";

		scmi61_pd: protocol@11 {
			reg = <0x11>;
			#power-domain-cells = <1>;
		};

		scmi61_dvfs: protocol@13 {
			reg = <0x13>;
			#power-domain-cells = <1>;
		};

		scmi61_rst: protocol@16 {
			reg = <0x16>;
			#reset-cells = <1>;
		};
	};

	scmi62: scmi-62 {
		compatible = "qcom,scmi-smc";
		arm,smc-id = <0xc6008012>;
		shmem = <&shmem62>;

		interrupts = <GIC_ESPI 37 IRQ_TYPE_EDGE_RISING>;
		interrupt-names = "a2p";

		#address-cells = <1>;
		#size-cells = <0>;

		status = "disabled";

		scmi62_pd: protocol@11 {
			reg = <0x11>;
			#power-domain-cells = <1>;
		};

		scmi62_dvfs: protocol@13 {
			reg = <0x13>;
			#power-domain-cells = <1>;
		};

		scmi62_rst: protocol@16 {
			reg = <0x16>;
			#reset-cells = <1>;
		};
	};

	scmi63: scmi-63 {
		compatible = "qcom,scmi-smc";
		arm,smc-id = <0xc6008012>;
		shmem = <&shmem63>;

		interrupts = <GIC_ESPI 38 IRQ_TYPE_EDGE_RISING>;
		interrupt-names = "a2p";

		#address-cells = <1>;
		#size-cells = <0>;

		status = "disabled";

		scmi63_pd: protocol@11 {
			reg = <0x11>;
			#power-domain-cells = <1>;
		};

		scmi63_dvfs: protocol@13 {
			reg = <0x13>;
			#power-domain-cells = <1>;
		};

		scmi63_rst: protocol@16 {
			reg = <0x16>;
			#reset-cells = <1>;
		};
	};

	pdp_scmi: qcom,pdp0-scmi {
		compatible = "arm,scmi";
		mboxes = <&pdp_mbox0 0>, <&pdp_mbox0 11>, <&pdp_mbox0 1>;
		mbox-names = "a2p_tx", "a2p_rx", "p2a";
		shmem = <&pdp0_a2p>, <&pdp0_p2a>;

		#address-cells = <1>;
		#size-cells = <0>;

		status = "disabled";

		cpu_perf: protocol@13 {
			reg = <0x13>;
			#clock-cells = <1>;
		};

		vendor_pdp: protocol@80 {
			reg = <0x80>;
			#clock-cells = <1>;
		};

	};

	pdp1_scmi: qcom,pdp1-scmi {
		compatible = "arm,scmi";
		mboxes = <&pdp_mbox1 0>, <&pdp_mbox1 12>;
		mbox-names = "a2p_tx1", "a2p_rx1";
		shmem = <&pdp1_a2p>;

		#address-cells = <1>;
		#size-cells = <0>;

		status = "disabled";

		vendor_pdp1: protocol@80 {
			reg = <0x80>;
			#clock-cells = <1>;
		};

	};

	pdp2_scmi: qcom,pdp2-scmi {
		compatible = "arm,scmi";
		mboxes = <&pdp_mbox2 0>, <&pdp_mbox2 13>;
		mbox-names = "a2p_tx2", "a2p_rx2";
		shmem = <&pdp2_a2p>;

		#address-cells = <1>;
		#size-cells = <0>;

		status = "disabled";

		vendor_pdp2: protocol@80 {
			reg = <0x80>;
			#clock-cells = <1>;
		};

	};

	cpucp_scmi: qcom,cpucp-scmi {
		compatible = "arm,scmi";
		mboxes = <&cpucp_mbox 0>, <&cpucp_mbox 2>;
		mbox-names = "tx", "rx";
		shmem = <&cpucp0_tx>, <&cpucp0_rx>;

		#address-cells = <1>;
		#size-cells = <0>;

		status = "disabled";

		vendor_cpupcp: protocol@80 {
			reg = <0x80>;
			#clock-cells = <1>;
		};
	};

	aop_scmi: qcom,aop-scmi {
		compatible = "arm,scmi";
		mboxes = <&ipcc0 IPCC_MPROC_AOP IPCC_MPROC_SIGNAL_SCMI_A2P>,
				<&ipcc0 IPCC_MPROC_AOP IPCC_MPROC_SIGNAL_SCMI_P2A>;
		mbox-names = "aop_a2p", "aop_p2a";
		shmem = <&aop0_a2p>, <&aop0_p2a>;

		#address-cells = <1>;
		#size-cells = <0>;

		status = "disabled";

		scmi_powercap: protocol@18 {
			reg = <0x18>;
		};
	};
};

&soc {
	scmichannels: sram@d7600000 {
		compatible = "mmio-sram";
		reg = <0x0 0xd7600000 0x0 0x40000>;
		ranges = <0x0 0x0 0x0 0xffffffff>;
		#address-cells = <1>;
		#size-cells = <1>;

		shmem0: scmi-sram@d7600000 {
			compatible = "arm,scmi-shmem";
			reg = <0xd7600000 0x1000>;
		};

		shmem1: scmi-sram@d7601000 {
			compatible = "arm,scmi-shmem";
			reg = <0xd7601000 0x1000>;
		};

		shmem2: scmi-sram@d7602000 {
			compatible = "arm,scmi-shmem";
			reg = <0xd7602000 0x1000>;
		};

		shmem3: scmi-sram@d7603000 {
			compatible = "arm,scmi-shmem";
			reg = <0xd7603000 0x1000>;
		};

		shmem4: scmi-sram@d7604000 {
			compatible = "arm,scmi-shmem";
			reg = <0xd7604000 0x1000>;
		};

		shmem5: scmi-sram@d7605000 {
			compatible = "arm,scmi-shmem";
			reg = <0xd7605000 0x1000>;
		};

		shmem6: scmi-sram@d7606000 {
			compatible = "arm,scmi-shmem";
			reg = <0xd7606000 0x1000>;
		};

		shmem7: scmi-sram@d7607000 {
			compatible = "arm,scmi-shmem";
			reg = <0xd7607000 0x1000>;
		};

		shmem8: scmi-sram@d7608000 {
			compatible = "arm,scmi-shmem";
			reg = <0xd7608000 0x1000>;
		};

		shmem9: scmi-sram@d7609000 {
			compatible = "arm,scmi-shmem";
			reg = <0xd7609000 0x1000>;
		};

		shmem10: scmi-sram@d760a000 {
			compatible = "arm,scmi-shmem";
			reg = <0xd760a000 0x1000>;
		};

		shmem11: scmi-sram@d760b000 {
			compatible = "arm,scmi-shmem";
			reg = <0xd760b000 0x1000>;
		};

		shmem12: scmi-sram@d760c000 {
			compatible = "arm,scmi-shmem";
			reg = <0xd760c000 0x1000>;
		};

		shmem13: scmi-sram@d760d000 {
			compatible = "arm,scmi-shmem";
			reg = <0xd760d000 0x1000>;
		};

		shmem14: scmi-sram@d760e000 {
			compatible = "arm,scmi-shmem";
			reg = <0xd760e000 0x1000>;
		};

		shmem15: scmi-sram@d760f000 {
			compatible = "arm,scmi-shmem";
			reg = <0xd760f000 0x1000>;
		};

		shmem16: scmi-sram@d7610000 {
			compatible = "arm,scmi-shmem";
			reg = <0xd7610000 0x1000>;
		};

		shmem17: scmi-sram@d7611000 {
			compatible = "arm,scmi-shmem";
			reg = <0xd7611000 0x1000>;
		};

		shmem18: scmi-sram@d7612000 {
			compatible = "arm,scmi-shmem";
			reg = <0xd7612000 0x1000>;
		};

		shmem19: scmi-sram@d7613000 {
			compatible = "arm,scmi-shmem";
			reg = <0xd7613000 0x1000>;
		};

		shmem20: scmi-sram@d7614000 {
			compatible = "arm,scmi-shmem";
			reg = <0xd7614000 0x1000>;
		};

		shmem21: scmi-sram@d7615000 {
			compatible = "arm,scmi-shmem";
			reg = <0xd7615000 0x1000>;
		};

		shmem22: scmi-sram@d7616000 {
			compatible = "arm,scmi-shmem";
			reg = <0xd7616000 0x1000>;
		};

		shmem23: scmi-sram@d7617000 {
			compatible = "arm,scmi-shmem";
			reg = <0xd7617000 0x1000>;
		};

		shmem24: scmi-sram@d7618000 {
			compatible = "arm,scmi-shmem";
			reg = <0xd7618000 0x1000>;
		};

		shmem25: scmi-sram@d7619000 {
			compatible = "arm,scmi-shmem";
			reg = <0xd7619000 0x1000>;
		};

		shmem26: scmi-sram@d761a000 {
			compatible = "arm,scmi-shmem";
			reg = <0xd761a000 0x1000>;
		};

		shmem27: scmi-sram@d761b000 {
			compatible = "arm,scmi-shmem";
			reg = <0xd761b000 0x1000>;
		};

		shmem28: scmi-sram@d761c000 {
			compatible = "arm,scmi-shmem";
			reg = <0xd761c000 0x1000>;
		};

		shmem29: scmi-sram@d761d000 {
			compatible = "arm,scmi-shmem";
			reg = <0xd761d000 0x1000>;
		};

		shmem30: scmi-sram@d761e000 {
			compatible = "arm,scmi-shmem";
			reg = <0xd761e000 0x1000>;
		};

		shmem31: scmi-sram@d761f000 {
			compatible = "arm,scmi-shmem";
			reg = <0xd761f000 0x1000>;
		};

		shmem32: scmi-sram@d7620000 {
			compatible = "arm,scmi-shmem";
			reg = <0xd7620000 0x1000>;
		};

		shmem33: scmi-sram@d7621000 {
			compatible = "arm,scmi-shmem";
			reg = <0xd7621000 0x1000>;
		};

		shmem34: scmi-sram@d7622000 {
			compatible = "arm,scmi-shmem";
			reg = <0xd7622000 0x1000>;
		};

		shmem35: scmi-sram@d7623000 {
			compatible = "arm,scmi-shmem";
			reg = <0xd7623000 0x1000>;
		};

		shmem36: scmi-sram@d7624000 {
			compatible = "arm,scmi-shmem";
			reg = <0xd7624000 0x1000>;
		};

		shmem37: scmi-sram@d7625000 {
			compatible = "arm,scmi-shmem";
			reg = <0xd7625000 0x1000>;
		};

		shmem38: scmi-sram@d7626000 {
			compatible = "arm,scmi-shmem";
			reg = <0xd7626000 0x1000>;
		};

		shmem39: scmi-sram@d7627000 {
			compatible = "arm,scmi-shmem";
			reg = <0xd7627000 0x1000>;
		};

		shmem40: scmi-sram@d7628000 {
			compatible = "arm,scmi-shmem";
			reg = <0xd7628000 0x1000>;
		};

		shmem41: scmi-sram@d7629000 {
			compatible = "arm,scmi-shmem";
			reg = <0xd7629000 0x1000>;
		};

		shmem42: scmi-sram@d762a000 {
			compatible = "arm,scmi-shmem";
			reg = <0xd762a000 0x1000>;
		};

		shmem43: scmi-sram@d762b000 {
			compatible = "arm,scmi-shmem";
			reg = <0xd762b000 0x1000>;
		};

		shmem44: scmi-sram@d762c000 {
			compatible = "arm,scmi-shmem";
			reg = <0xd762c000 0x1000>;
		};

		shmem45: scmi-sram@d762d000 {
			compatible = "arm,scmi-shmem";
			reg = <0xd762d000 0x1000>;
		};

		shmem46: scmi-sram@d762e000 {
			compatible = "arm,scmi-shmem";
			reg = <0xd762e000 0x1000>;
		};

		shmem47: scmi-sram@d762f000 {
			compatible = "arm,scmi-shmem";
			reg = <0xd762f000 0x1000>;
		};

		shmem48: scmi-sram@d7630000 {
			compatible = "arm,scmi-shmem";
			reg = <0xd7630000 0x1000>;
		};

		shmem49: scmi-sram@d7631000 {
			compatible = "arm,scmi-shmem";
			reg = <0xd7631000 0x1000>;
		};

		shmem50: scmi-sram@d7632000 {
			compatible = "arm,scmi-shmem";
			reg = <0xd7632000 0x1000>;
		};

		shmem51: scmi-sram@d7633000 {
			compatible = "arm,scmi-shmem";
			reg = <0xd7633000 0x1000>;
		};

		shmem52: scmi-sram@d7634000 {
			compatible = "arm,scmi-shmem";
			reg = <0xd7634000 0x1000>;
		};

		shmem53: scmi-sram@d7635000 {
			compatible = "arm,scmi-shmem";
			reg = <0xd7635000 0x1000>;
		};

		shmem54: scmi-sram@d7636000 {
			compatible = "arm,scmi-shmem";
			reg = <0xd7636000 0x1000>;
		};

		shmem55: scmi-sram@d7637000 {
			compatible = "arm,scmi-shmem";
			reg = <0xd7637000 0x1000>;
		};

		shmem56: scmi-sram@d7638000 {
			compatible = "arm,scmi-shmem";
			reg = <0xd7638000 0x1000>;
		};

		shmem57: scmi-sram@d7639000 {
			compatible = "arm,scmi-shmem";
			reg = <0xd7639000 0x1000>;
		};

		shmem58: scmi-sram@d763a000 {
			compatible = "arm,scmi-shmem";
			reg = <0xd763a000 0x1000>;
		};

		shmem59: scmi-sram@d763b000 {
			compatible = "arm,scmi-shmem";
			reg = <0xd763b000 0x1000>;
		};

		shmem60: scmi-sram@d763c000 {
			compatible = "arm,scmi-shmem";
			reg = <0xd763c000 0x1000>;
		};

		shmem61: scmi-sram@d763d000 {
			compatible = "arm,scmi-shmem";
			reg = <0xd763d000 0x1000>;
		};

		shmem62: scmi-sram@d763e000 {
			compatible = "arm,scmi-shmem";
			reg = <0xd763e000 0x1000>;
		};

		shmem63: scmi-sram@d763f000 {
			compatible = "arm,scmi-shmem";
			reg = <0xd763f000 0x1000>;
		};
	};

	pdp_sram: pdp-sram@0x87608000 {
		#address-cells = <1>;
		#size-cells = <1>;
		compatible = "mmio-sram";
		reg = <0x0 0x87608000 0x0 0x300>;
		ranges = <0 0x0 0x87608000 0x300>;

		pdp0_p2a: scmi-shmem@0 {
			compatible = "arm,scmi-shmem";
			reg = <0x0 0x80>;
		};

		pdp0_a2p: scmi-shmem@180 {
			compatible = "arm,scmi-shmem";
			reg = <0x180 0x80>;
		};

		pdp1_p2a: scmi-shmem@80 {
			compatible = "arm,scmi-shmem";
			reg = <0x80 0x80>;
		};

		pdp1_a2p: scmi-shmem@200 {
			compatible = "arm,scmi-shmem";
			reg = <0x200 0x80>;
		};

		pdp2_p2a: scmi-shmem@100 {
			compatible = "arm,scmi-shmem";
			reg = <0x100 0x80>;
		};

		pdp2_a2p: scmi-shmem@280 {
			compatible = "arm,scmi-shmem";
			reg = <0x280 0x80>;
		};

	};

	cpucp_sram: cpucp-sram@18b3d000 {
		#address-cells = <1>;
		#size-cells = <1>;
		compatible = "mmio-sram";
		reg = <0x0 0x18b3d000 0x0 0x400>;
		ranges = <0 0x0 0x18b3d000 0x400>;

		cpucp0_tx: scmi-shmem@0 {
			compatible = "arm,scmi-shmem";
			reg = <0x0 0x200>;
		};

		cpucp0_rx: scmi-shmem@200 {
			compatible = "arm,scmi-shmem";
			reg = <0x200 0x200>;
		};

	};

	aop_sram_tx: aop-sram@c319000 {
		#address-cells = <1>;
		#size-cells = <1>;
		compatible = "mmio-sram";
		reg = <0x0 0xc319000 0x0 0x400>;
		ranges = <0 0x0 0xc319000 0x400>;

		aop0_a2p: aop0-a2p@0 {
			compatible = "arm,scmi-shmem";
			reg = <0x0 0x400>;
			reg-io-width = <4>;
		};
	};

	aop_sram_rx: aop-sram@c31a000 {
		#address-cells = <1>;
		#size-cells = <1>;
		compatible = "mmio-sram";
		reg = <0x0 0xc31a000 0x0 0x400>;
		ranges = <0 0x0 0xc31a000 0x400>;

		aop0_p2a: aop0-p2a@0 {
			compatible = "arm,scmi-shmem";
			reg = <0x0 0x400>;
			reg-io-width = <4>;
		};
	};
};
